VERSION "1.0"

NS_ :

BS_:
BU_: TEENSY1 TEENSY2 TEENSY3 TEENSY4 CONTROLLER HOST

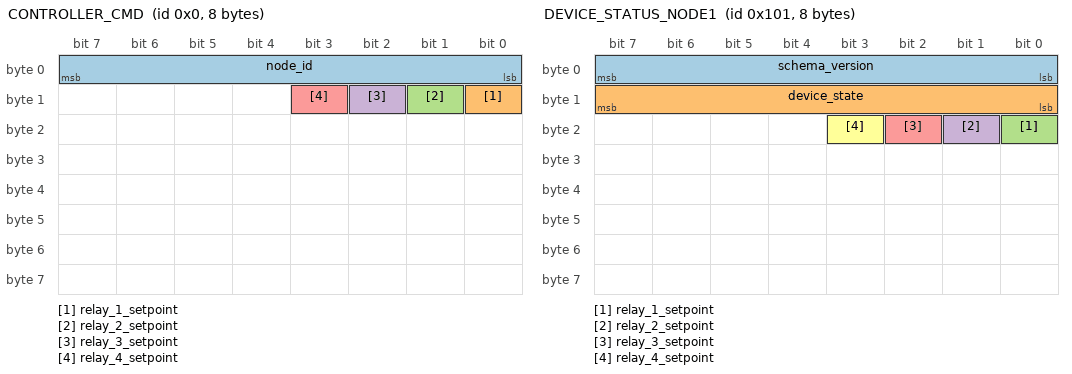
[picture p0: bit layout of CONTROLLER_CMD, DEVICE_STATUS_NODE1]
BO_ 0 CONTROLLER_CMD: 8 CONTROLLER
   SG_ node_id : 0|8@1+ (1,0) [0|255] "" HOST
   SG_ relay_1_setpoint : 8|1@1+ (1,0) [0|1] "" HOST
   SG_ relay_2_setpoint : 9|1@1+ (1,0) [0|1] "" HOST
   SG_ relay_3_setpoint : 10|1@1+ (1,0) [0|1] "" HOST
   SG_ relay_4_setpoint : 11|1@1+ (1,0) [0|1] "" HOST

BO_ 257 DEVICE_STATUS_NODE1: 8 TEENSY1
   SG_ schema_version : 0|8@1+ (1,0) [0|255] "" HOST
   SG_ device_state : 8|8@1+ (1,0) [0|2] "" HOST
   SG_ relay_1_setpoint : 16|1@1+ (1,0) [0|1] "" HOST
   SG_ relay_2_setpoint : 17|1@1+ (1,0) [0|1] "" HOST
   SG_ relay_3_setpoint : 18|1@1+ (1,0) [0|1] "" HOST
   SG_ relay_4_setpoint : 19|1@1+ (1,0) [0|1] "" HOST

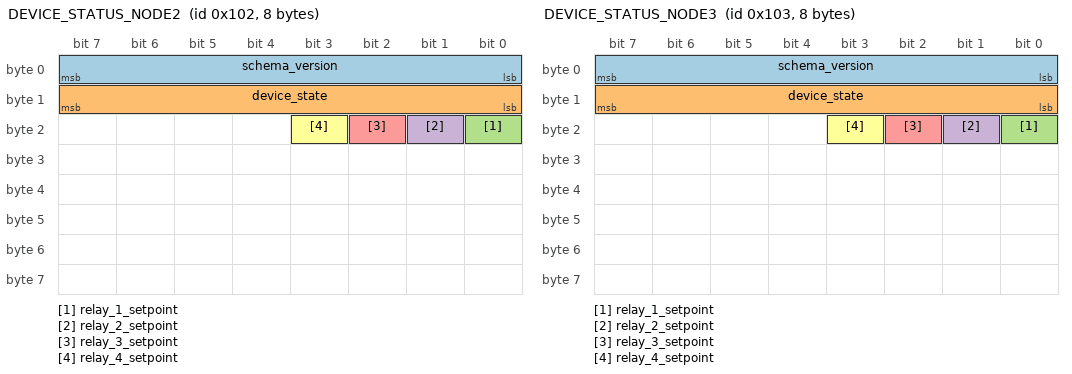
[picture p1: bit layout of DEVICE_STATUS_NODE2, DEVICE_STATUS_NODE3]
BO_ 258 DEVICE_STATUS_NODE2: 8 TEENSY2
   SG_ schema_version : 0|8@1+ (1,0) [0|255] "" HOST
   SG_ device_state : 8|8@1+ (1,0) [0|2] "" HOST
   SG_ relay_1_setpoint : 16|1@1+ (1,0) [0|1] "" HOST
   SG_ relay_2_setpoint : 17|1@1+ (1,0) [0|1] "" HOST
   SG_ relay_3_setpoint : 18|1@1+ (1,0) [0|1] "" HOST
   SG_ relay_4_setpoint : 19|1@1+ (1,0) [0|1] "" HOST

BO_ 259 DEVICE_STATUS_NODE3: 8 TEENSY3
   SG_ schema_version : 0|8@1+ (1,0) [0|255] "" HOST
   SG_ device_state : 8|8@1+ (1,0) [0|2] "" HOST
   SG_ relay_1_setpoint : 16|1@1+ (1,0) [0|1] "" HOST
   SG_ relay_2_setpoint : 17|1@1+ (1,0) [0|1] "" HOST
   SG_ relay_3_setpoint : 18|1@1+ (1,0) [0|1] "" HOST
   SG_ relay_4_setpoint : 19|1@1+ (1,0) [0|1] "" HOST

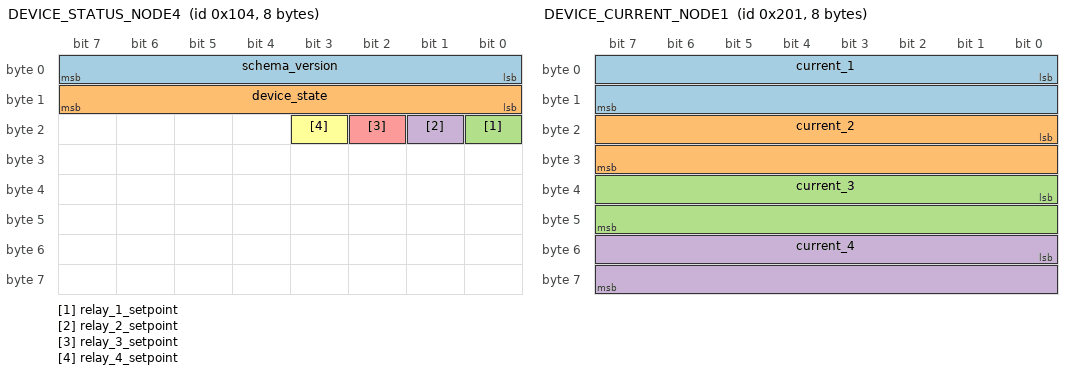
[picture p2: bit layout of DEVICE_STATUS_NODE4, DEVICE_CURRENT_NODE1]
BO_ 260 DEVICE_STATUS_NODE4: 8 TEENSY4
   SG_ schema_version : 0|8@1+ (1,0) [0|255] "" HOST
   SG_ device_state : 8|8@1+ (1,0) [0|2] "" HOST
   SG_ relay_1_setpoint : 16|1@1+ (1,0) [0|1] "" HOST
   SG_ relay_2_setpoint : 17|1@1+ (1,0) [0|1] "" HOST
   SG_ relay_3_setpoint : 18|1@1+ (1,0) [0|1] "" HOST
   SG_ relay_4_setpoint : 19|1@1+ (1,0) [0|1] "" HOST

BO_ 513 DEVICE_CURRENT_NODE1: 8 TEENSY1
   SG_ current_1 : 0|16@1+ (0.1,0) [0|6553.5] "A" HOST
   SG_ current_2 : 16|16@1+ (0.1,0) [0|6553.5] "A" HOST
   SG_ current_3 : 32|16@1+ (0.1,0) [0|6553.5] "A" HOST
   SG_ current_4 : 48|16@1+ (0.1,0) [0|6553.5] "A" HOST

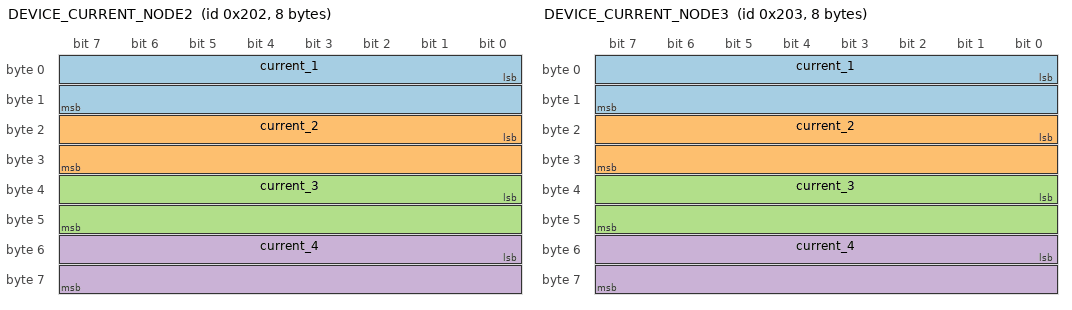
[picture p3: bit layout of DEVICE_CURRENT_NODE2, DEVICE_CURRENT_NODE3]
BO_ 514 DEVICE_CURRENT_NODE2: 8 TEENSY2
   SG_ current_1 : 0|16@1+ (0.1,0) [0|6553.5] "A" HOST
   SG_ current_2 : 16|16@1+ (0.1,0) [0|6553.5] "A" HOST
   SG_ current_3 : 32|16@1+ (0.1,0) [0|6553.5] "A" HOST
   SG_ current_4 : 48|16@1+ (0.1,0) [0|6553.5] "A" HOST

BO_ 515 DEVICE_CURRENT_NODE3: 8 TEENSY3
   SG_ current_1 : 0|16@1+ (0.1,0) [0|6553.5] "A" HOST
   SG_ current_2 : 16|16@1+ (0.1,0) [0|6553.5] "A" HOST
   SG_ current_3 : 32|16@1+ (0.1,0) [0|6553.5] "A" HOST
   SG_ current_4 : 48|16@1+ (0.1,0) [0|6553.5] "A" HOST

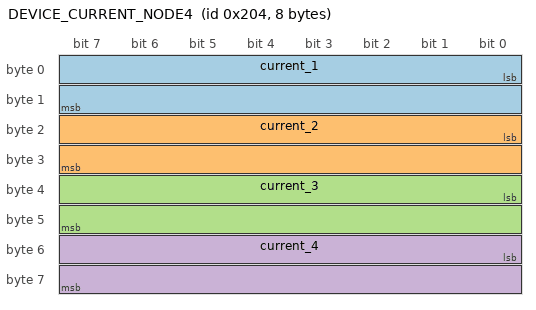
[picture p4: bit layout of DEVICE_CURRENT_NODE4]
BO_ 516 DEVICE_CURRENT_NODE4: 8 TEENSY4
   SG_ current_1 : 0|16@1+ (0.1,0) [0|6553.5] "A" HOST
   SG_ current_2 : 16|16@1+ (0.1,0) [0|6553.5] "A" HOST
   SG_ current_3 : 32|16@1+ (0.1,0) [0|6553.5] "A" HOST
   SG_ current_4 : 48|16@1+ (0.1,0) [0|6553.5] "A" HOST

BA_DEF_ BO_ "GenMsgCycleTime" INT 0 65535;
BA_DEF_ BO_ "GenMsgBackgroundColor" STRING ;
BA_DEF_ BO_ "GenMsgForegroundColor" STRING ;
BA_ "GenMsgCycleTime" BO_ 257 1000;
BA_ "GenMsgCycleTime" BO_ 258 1000;
BA_ "GenMsgCycleTime" BO_ 259 1000;
BA_ "GenMsgCycleTime" BO_ 260 1000;
BA_DEF_DEF_ "GenMsgBackgroundColor" "#ffffff";
BA_DEF_DEF_ "GenMsgForegroundColor" "#000000";
